# COMPUTE_CLUSTER_J7AHP0_DRU_0_MMR_DRU0_MMR_CFG_DRU_CHCORE register map
Vendor: Texas Instruments
Peripheral module from a debugger description file (folder J7_AHP).
Registers are 64-bit, write-only, reset 0x0 unless marked. A register's access mark holds for its fields unless they carry their own. Offsets are as the file gives them; lines under a group give offsets from that group; [hi:lo] are bit positions; {n}, {i} and the like mark numbered series; 'fields as' and 'values as' point back to an identical list; <NAME> marks a mode.

## COMPUTE_CLUSTER_J7AHP0_DRU_0_MMR_DRU0_MMR_CFG_DRU_CHCORE
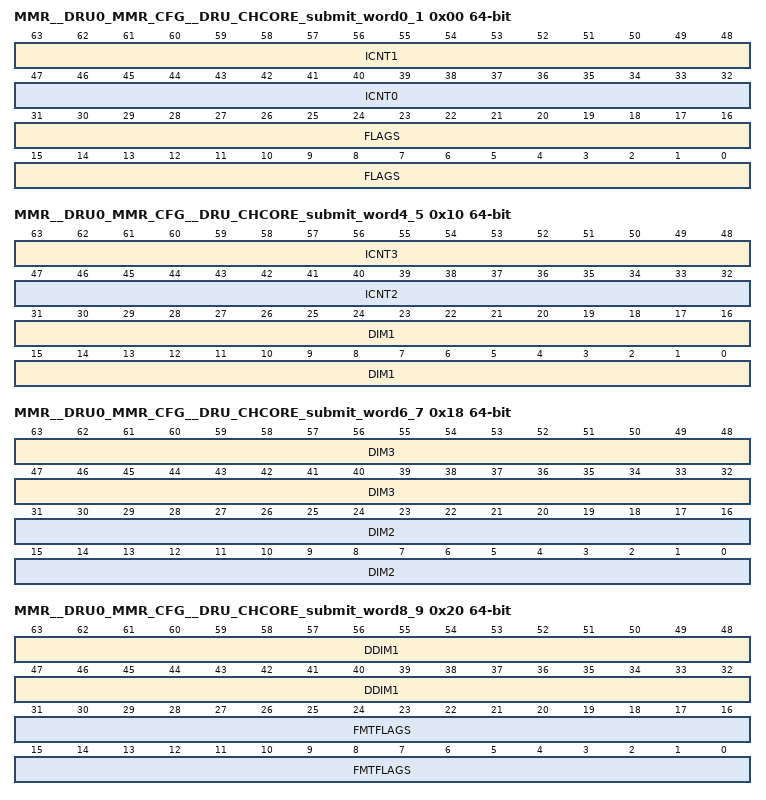
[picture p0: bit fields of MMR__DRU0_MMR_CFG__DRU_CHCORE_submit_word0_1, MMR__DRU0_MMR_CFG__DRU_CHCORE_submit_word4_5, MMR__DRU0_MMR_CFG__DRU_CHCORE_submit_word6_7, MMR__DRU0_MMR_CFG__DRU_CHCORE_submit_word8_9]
0x00 MMR__DRU0_MMR_CFG__DRU_CHCORE_submit_word0_1
  [63:48] ICNT1 — Lines in a transfer
  [47:32] ICNT0 — Bytes in a transfer
  [31:0] FLAGS — Flags for the operation and type of descriptor
0x08 MMR__DRU0_MMR_CFG__DRU_CHCORE_submit_word2_3
  [47:0] SRC_ADDR — Source transfer address virtual or physical allowed
0x10 MMR__DRU0_MMR_CFG__DRU_CHCORE_submit_word4_5
  [63:48] ICNT3 — The size of the 4th loop in the TR transfer
  [47:32] ICNT2 — The size of the 3rd loop in the TR transfer
  [31:0] DIM1 — The first dimension width of the source data
0x18 MMR__DRU0_MMR_CFG__DRU_CHCORE_submit_word6_7
  [63:32] DIM3 — The third dimension width of the source data
  [31:0] DIM2 — The second dimension width of the source data
0x20 MMR__DRU0_MMR_CFG__DRU_CHCORE_submit_word8_9
  [63:32] DDIM1 — The first dimension width of the destination data
  [31:0] FMTFLAGS — The data formatting flags to be used for the TR
0x28 MMR__DRU0_MMR_CFG__DRU_CHCORE_submit_word10_11
  [47:0] DADDR — Destination transfer address virtual or physical allowed
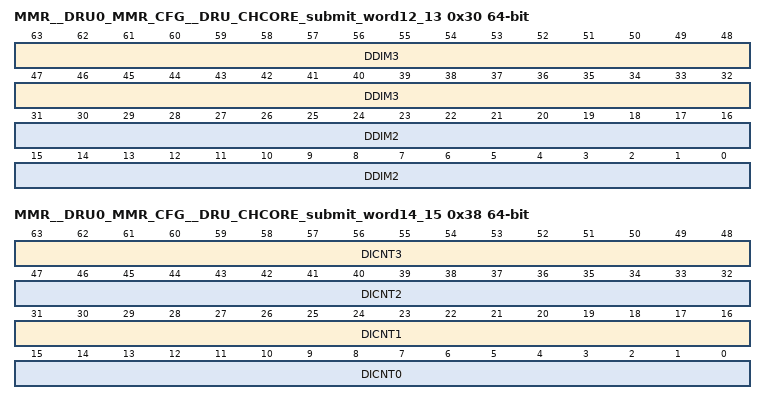
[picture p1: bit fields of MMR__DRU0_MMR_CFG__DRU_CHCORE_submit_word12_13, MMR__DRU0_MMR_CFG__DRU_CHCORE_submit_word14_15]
0x30 MMR__DRU0_MMR_CFG__DRU_CHCORE_submit_word12_13
  [63:32] DDIM3 — The third dimension width of the destination data
  [31:0] DDIM2 — The second dimension width of the destination data
0x38 MMR__DRU0_MMR_CFG__DRU_CHCORE_submit_word14_15
  [63:48] DICNT3 — The fourth count of the destination if different than the source
  [47:32] DICNT2 — The third count of the destination if different than the source
  [31:16] DICNT1 — The second innermost count of the destination if different than the source
  [15:0] DICNT0 — The innermost count of the destination if different than the source
